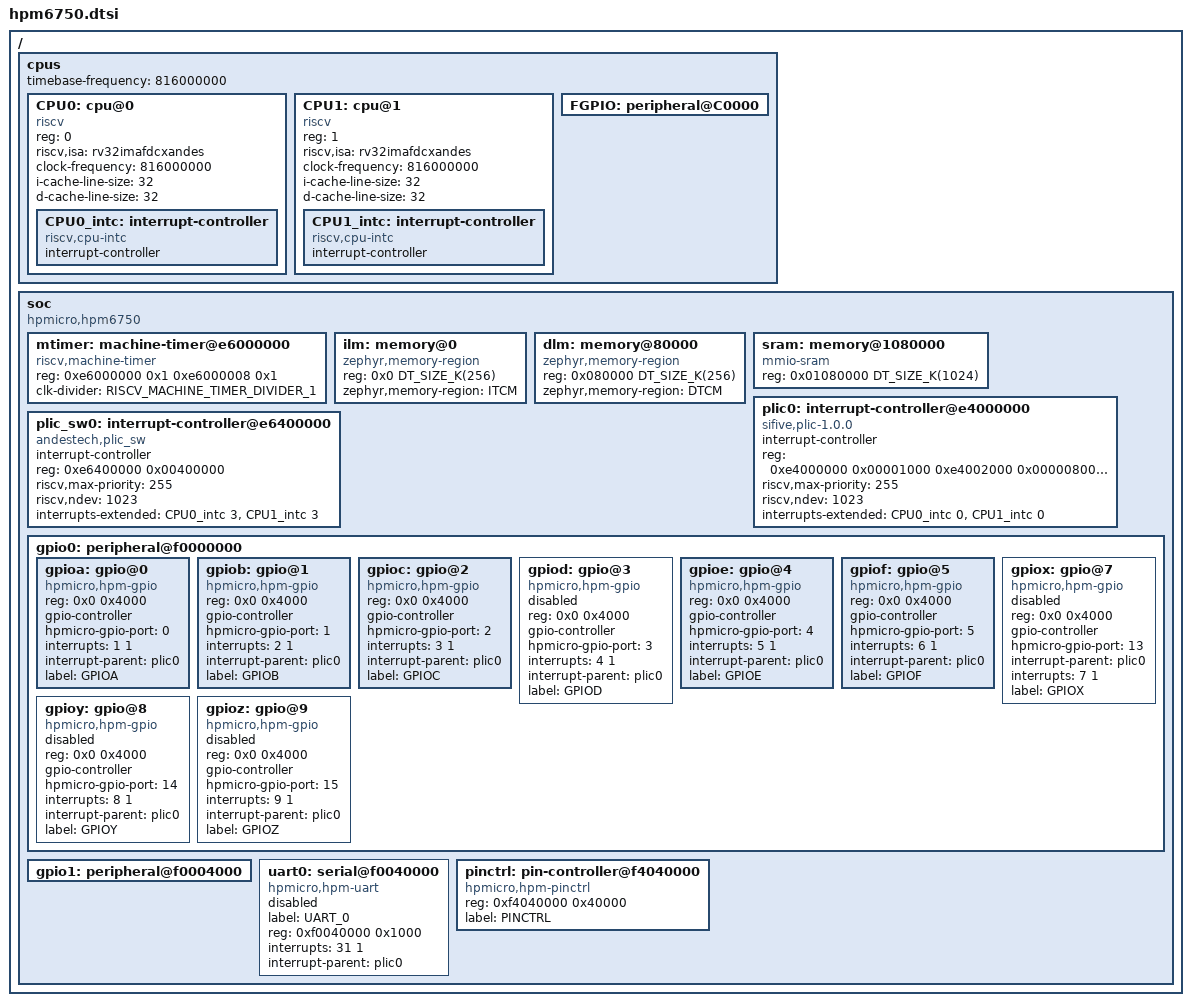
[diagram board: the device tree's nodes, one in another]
/*
 * Copyright 2022 hpmicro
 * SPDX-License-Identifier: Apache-2.0
 */

/dts-v1/;
#include <dt-bindings/gpio/gpio.h>
#include <zephyr/dt-bindings/timer/riscv-machine-timer.h>
#include <mem.h>

/ {
	#address-cells = <1>;
	#size-cells = <1>;

	cpus {
		#address-cells = <1>;
		#size-cells = <0>;
		timebase-frequency = <816000000>;
		CPU0: cpu@0 {
			compatible = "riscv";
			device_type = "cpu";
			reg = <0>;
			status = "okay";
			riscv,isa = "rv32imafdcxandes";
			clock-frequency = <816000000>;
			i-cache-line-size = <32>;
			d-cache-line-size = <32>;
			CPU0_intc: interrupt-controller {
				#interrupt-cells = <1>;
				interrupt-controller;
				compatible = "riscv,cpu-intc";
			};
		};
		CPU1: cpu@1 {
			compatible = "riscv";
			device_type = "cpu";
			reg = <1>;
			status = "okay";
			riscv,isa = "rv32imafdcxandes";
			clock-frequency = <816000000>;
			i-cache-line-size = <32>;
			d-cache-line-size = <32>;
			CPU1_intc: interrupt-controller {
				#interrupt-cells = <1>;
				interrupt-controller;
				compatible = "riscv,cpu-intc";
			};
		};

		FGPIO: peripheral@C0000 {
			#address-cells = <1>;
			#size-cells = <1>;
			ranges = <0x0 0xC0000 0x2000>;
		};
	};

	soc {
		#address-cells = <1>;
		#size-cells = <1>;
		compatible = "hpmicro,hpm6750";
		ranges;

		mtimer: machine-timer@e6000000 {
			compatible = "riscv,machine-timer";
			reg = <0xe6000000 0x1
			       0xe6000008 0x1>;
			clk-divider = <RISCV_MACHINE_TIMER_DIVIDER_1>;
		};

		ilm: memory@0 {
			compatible = "zephyr,memory-region";
			reg = <0x0 DT_SIZE_K(256)>;
			zephyr,memory-region = "ITCM";
		};

		dlm: memory@80000 {
			compatible = "zephyr,memory-region";
			reg = <0x080000 DT_SIZE_K(256)>;
			zephyr,memory-region = "DTCM";
		};

		sram: memory@1080000 {
			device_type = "memory";
			compatible = "mmio-sram";
			reg = <0x01080000 DT_SIZE_K(1024)>;
		};

		plic0: interrupt-controller@e4000000 {
			compatible = "sifive,plic-1.0.0";
			#address-cells = <1>;
			#interrupt-cells = <2>;
			interrupt-controller;
			reg = <	0xe4000000 0x00001000
				0xe4002000 0x00000800
				0xe4200000 0x00010000 >;
			reg-names = "prio", "irq_en", "reg";
			riscv,max-priority = <255>;
			riscv,ndev = <1023>;
			interrupts-extended = <&CPU0_intc 0 &CPU1_intc 0>;
		};

		plic_sw0: interrupt-controller@e6400000 {
			compatible = "andestech,plic_sw";
			#address-cells = <1>;
			#interrupt-cells = <2>;
			interrupt-controller;
			reg = <0xe6400000 0x00400000>;
			riscv,max-priority = <255>;
			riscv,ndev = <1023>;
			interrupts-extended = <&CPU0_intc 3 &CPU1_intc 3>;
		};

		gpio0: peripheral@f0000000 {
			#address-cells = <1>;
			#size-cells = <1>;
			ranges = <0x0 0xf0000000 0x4000>;
		};

		gpio1: peripheral@f0004000 {
			#address-cells = <1>;
			#size-cells = <1>;
			ranges = <0x0 0xf0004000 0x4000>;
		};

		uart0: serial@f0040000 {
			compatible = "hpmicro,hpm-uart";
			label = "UART_0";
			reg = <0xf0040000 0x1000>;
			interrupts = <31 1>;
			interrupt-parent = <&plic0>;
			status = "disabled";
		};

		pinctrl: pin-controller@f4040000 {
			compatible = "hpmicro,hpm-pinctrl";
			reg = <0xf4040000 0x40000>;
			status = "okay";
			label = "PINCTRL";
		};
	};
};

&gpio0 {
	gpioa: gpio@0 {
		compatible = "hpmicro,hpm-gpio";
		reg = <0x0 0x4000>;
		gpio-controller;
		#gpio-cells = <2>;
		hpmicro-gpio-port = <0>;
		interrupts = <1 1>;
		interrupt-parent = <&plic0>;
		label = "GPIOA";
	};

	gpiob: gpio@1 {
		compatible = "hpmicro,hpm-gpio";
		reg = <0x0 0x4000>;
		gpio-controller;
		#gpio-cells = <2>;
		hpmicro-gpio-port = <1>;
		interrupts = <2 1>;
		interrupt-parent = <&plic0>;
		label = "GPIOB";
	};

	gpioc: gpio@2 {
		compatible = "hpmicro,hpm-gpio";
		reg = <0x0 0x4000>;
		gpio-controller;
		#gpio-cells = <2>;
		hpmicro-gpio-port = <2>;
		interrupts = <3 1>;
		interrupt-parent = <&plic0>;
		label = "GPIOC";
	};

	gpiod: gpio@3 {
		compatible = "hpmicro,hpm-gpio";
		reg = <0x0 0x4000>;
		gpio-controller;
		#gpio-cells = <2>;
		status = "disabled";
		hpmicro-gpio-port = <3>;
		interrupts = <4 1>;
		interrupt-parent = <&plic0>;
		label = "GPIOD";
	};

	gpioe: gpio@4 {
		compatible = "hpmicro,hpm-gpio";
		reg = <0x0 0x4000>;
		gpio-controller;
		#gpio-cells = <2>;
		hpmicro-gpio-port = <4>;
		interrupts = <5 1>;
		interrupt-parent = <&plic0>;
		label = "GPIOE";
	};

	gpiof: gpio@5 {
		compatible = "hpmicro,hpm-gpio";
		reg = <0x0 0x4000>;
		gpio-controller;
		#gpio-cells = <2>;
		hpmicro-gpio-port = <5>;
		interrupts = <6 1>;
		interrupt-parent = <&plic0>;
		label = "GPIOF";
	};

	gpiox: gpio@7 {
		compatible = "hpmicro,hpm-gpio";
		reg = <0x0 0x4000>;
		gpio-controller;
		#gpio-cells = <2>;
		hpmicro-gpio-port = <13>;
		interrupt-parent = <&plic0>;
		interrupts = <7 1>;
		status = "disabled";
		label = "GPIOX";
	};

	gpioy: gpio@8 {
		compatible = "hpmicro,hpm-gpio";
		reg = <0x0 0x4000>;
		gpio-controller;
		#gpio-cells = <2>;
		hpmicro-gpio-port = <14>;
		interrupts = <8 1>;
		interrupt-parent = <&plic0>;
		label = "GPIOY";
		status = "disabled";
	};

	gpioz: gpio@9 {
		compatible = "hpmicro,hpm-gpio";
		reg = <0x0 0x4000>;
		gpio-controller;
		#gpio-cells = <2>;
		hpmicro-gpio-port = <15>;
		interrupts = <9 1>;
		interrupt-parent = <&plic0>;
		label = "GPIOZ";
		status = "disabled";
	};
};
